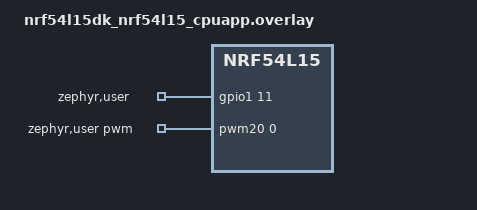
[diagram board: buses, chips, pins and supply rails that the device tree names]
/*
 * Copyright (c) 2024 Nordic Semiconductor ASA
 * SPDX-License-Identifier: Apache-2.0
 *
 * Test requires jumper between:
 *  - PWM20 OUT[0] at P1.10 <-> GPIO input at P1.11
 */

#include <zephyr/dt-bindings/pwm/pwm.h>
#include <zephyr/dt-bindings/gpio/gpio.h>
#include <zephyr/dt-bindings/gpio/nordic-nrf-gpio.h>

/ {
	zephyr,user {
		pwms = <&pwm20 0 160000 PWM_POLARITY_NORMAL>;
		gpios = <&gpio1 11 GPIO_ACTIVE_HIGH>;
	};
};
